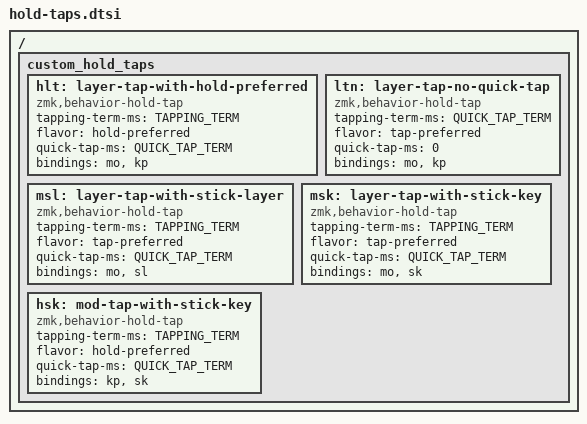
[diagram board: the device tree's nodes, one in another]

/ {
    custom_hold_taps {

        hlt: layer-tap-with-hold-preferred {
            compatible = "zmk,behavior-hold-tap";
            #binding-cells = <2>;
            tapping-term-ms = <TAPPING_TERM>;
            flavor = "hold-preferred";
            quick-tap-ms = <QUICK_TAP_TERM>;
            bindings = <&mo>, <&kp>;
        };

        ltn: layer-tap-no-quick-tap {
            compatible = "zmk,behavior-hold-tap";
            #binding-cells = <2>;
            tapping-term-ms = <QUICK_TAP_TERM>;
            flavor = "tap-preferred";
            quick-tap-ms = <0>;
            bindings = <&mo>, <&kp>;
        };

        msl: layer-tap-with-stick-layer {
            compatible = "zmk,behavior-hold-tap";
            #binding-cells = <2>;
            tapping-term-ms = <TAPPING_TERM>;
            flavor = "tap-preferred";
            quick-tap-ms = <QUICK_TAP_TERM>;
            bindings = <&mo>, <&sl>;
        };

        msk: layer-tap-with-stick-key {
            compatible = "zmk,behavior-hold-tap";
            #binding-cells = <2>;
            tapping-term-ms = <TAPPING_TERM>;
            flavor = "tap-preferred";
            quick-tap-ms = <QUICK_TAP_TERM>;
            bindings = <&mo>, <&sk>;
        };

        hsk: mod-tap-with-stick-key {
            compatible = "zmk,behavior-hold-tap";
            #binding-cells = <2>;
            tapping-term-ms = <TAPPING_TERM>;
            flavor = "hold-preferred";
            quick-tap-ms = <QUICK_TAP_TERM>;
            bindings = <&kp>, <&sk>;
        };

    };
};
